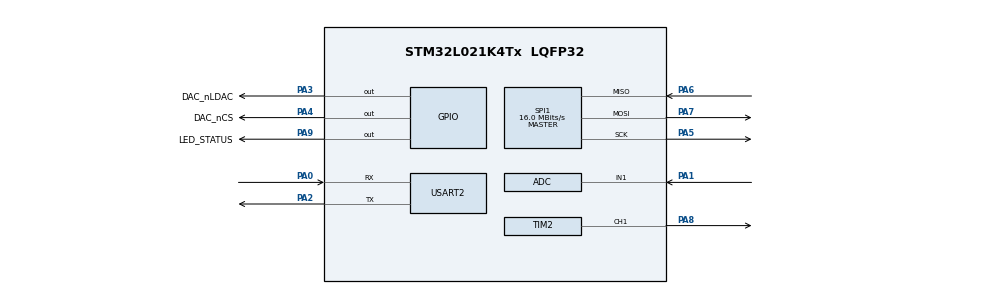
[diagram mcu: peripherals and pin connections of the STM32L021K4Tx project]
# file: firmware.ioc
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Mcu.Family=STM32L0
Mcu.Name=STM32L021K4Tx
Mcu.Package=LQFP32
PA0-CK_IN.Mode=Asynchronous
PA0-CK_IN.Signal=USART2_RX
PA1.Mode=IN1
PA1.Signal=ADC_IN1
PA13.Mode=Serial_Wire
PA13.Signal=SYS_SWDIO
PA14.Mode=Serial_Wire
PA14.Signal=SYS_SWCLK
PA2.Mode=Asynchronous
PA2.Signal=USART2_TX
PA3.GPIO_Label=DAC_nLDAC
PA3.Signal=GPIO_Output
PA4.GPIO_Label=DAC_nCS
PA4.Signal=GPIO_Output
PA5.Mode=Full_Duplex_Master
PA5.Signal=SPI1_SCK
PA6.Mode=Full_Duplex_Master
PA6.Signal=SPI1_MISO
PA7.Mode=Full_Duplex_Master
PA7.Signal=SPI1_MOSI
PA8.Signal=S_TIM2_CH1
PA9.GPIO_Label=LED_STATUS
PA9.Signal=GPIO_Output
ProjectManager.HeapSize=0x200
ProjectManager.StackSize=0x400
ProjectManager.TargetToolchain=EWARM V8.32
RCC.ADCFreq_Value=16000000
RCC.AHBFreq_Value=32000000
RCC.APB1Freq_Value=32000000
RCC.APB1TimFreq_Value=32000000
RCC.APB2Freq_Value=32000000
RCC.APB2TimFreq_Value=32000000
RCC.HCLKFreq_Value=32000000
RCC.HSE_VALUE=8000000
RCC.HSI16_VALUE=16000000
RCC.HSI_VALUE=16000000
RCC.LSE_VALUE=32768
RCC.MSI_VALUE=2097000
RCC.PLLMUL=RCC_PLLMUL_4
RCC.SYSCLKFreq_VALUE=32000000
RCC.SYSCLKSource=RCC_SYSCLKSOURCE_PLLCLK
RCC.VCOOutputFreq_Value=64000000
SH.S_TIM2_CH1.0=TIM2_CH1,PWM Generation1 CH1
SPI1.CalculateBaudRate=16.0 MBits/s
SPI1.Direction=SPI_DIRECTION_2LINES
SPI1.Mode=SPI_MODE_MASTER
SPI1.VirtualType=VM_MASTER
TIM2.Channel-PWM\ Generation1\ CH1=TIM_CHANNEL_1
TIM2.Period=255
TIM2.Prescaler=128
USART2.VirtualMode-Asynchronous=VM_ASYNC
VP_TIM2_VS_ClockSourceINT.Mode=Internal
board=custom

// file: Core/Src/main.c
/* USER CODE BEGIN Header */
/**
  ******************************************************************************
  * @file           : main.c
  * @brief          : Main program body
  ******************************************************************************
  * @attention
  *
  * Copyright (c) 2023 STMicroelectronics.
  * All rights reserved.
  *
  * This software is licensed under terms that can be found in the LICENSE file
  * in the root directory of this software component.
  * If no LICENSE file comes with this software, it is provided AS-IS.
  *
  ******************************************************************************
  */
/* USER CODE END Header */
#include "main.h"
#include "adc.h"
#include "spi.h"
#include "tim.h"
#include "usart.h"
#include "gpio.h"

void SystemClock_Config(void);

int main(void)
{

  /* MCU Configuration--------------------------------------------------------*/

  /* Reset of all peripherals, Initializes the Flash interface and the Systick. */
  LL_APB2_GRP1_EnableClock(LL_APB2_GRP1_PERIPH_SYSCFG);
  LL_APB1_GRP1_EnableClock(LL_APB1_GRP1_PERIPH_PWR);

  /* SysTick_IRQn interrupt configuration */
  NVIC_SetPriority(SysTick_IRQn, 3);

  /* Configure the system clock */
  SystemClock_Config();

  /* Initialize all configured peripherals */
  MX_GPIO_Init();
  MX_USART2_UART_Init();
  MX_ADC_Init();
  MX_SPI1_Init();
  MX_TIM2_Init();

  /* Infinite loop */
  /* USER CODE BEGIN WHILE */
  LedStart();
  while (1)
  {
	      LedPulse();
	 	  LL_mDelay(1);
    /* USER CODE END WHILE */

  }
}

void SystemClock_Config(void)
{
  LL_FLASH_SetLatency(LL_FLASH_LATENCY_1);
  while(LL_FLASH_GetLatency()!= LL_FLASH_LATENCY_1)
  {
  }
  LL_PWR_SetRegulVoltageScaling(LL_PWR_REGU_VOLTAGE_SCALE1);
  while (LL_PWR_IsActiveFlag_VOS() == 0)
  {
  }
  LL_RCC_HSI_Enable();

   /* Wait till HSI is ready */
  while(LL_RCC_HSI_IsReady() != 1)
  {

  }
  LL_RCC_HSI_SetCalibTrimming(16);
  LL_RCC_PLL_ConfigDomain_SYS(LL_RCC_PLLSOURCE_HSI, LL_RCC_PLL_MUL_4, LL_RCC_PLL_DIV_2);
  LL_RCC_PLL_Enable();

   /* Wait till PLL is ready */
  while(LL_RCC_PLL_IsReady() != 1)
  {

  }
  LL_RCC_SetAHBPrescaler(LL_RCC_SYSCLK_DIV_1);
  LL_RCC_SetAPB1Prescaler(LL_RCC_APB1_DIV_1);
  LL_RCC_SetAPB2Prescaler(LL_RCC_APB2_DIV_1);
  LL_RCC_SetSysClkSource(LL_RCC_SYS_CLKSOURCE_PLL);

   /* Wait till System clock is ready */
  while(LL_RCC_GetSysClkSource() != LL_RCC_SYS_CLKSOURCE_STATUS_PLL)
  {

  }

  LL_Init1msTick(32000000);

  LL_SetSystemCoreClock(32000000);
  LL_RCC_SetUSARTClockSource(LL_RCC_USART2_CLKSOURCE_PCLK1);
}

void Error_Handler(void)
{
  __disable_irq();
  while (1)
  {
  }
}
